# MSP432P401Y register map
Vendor: Texas Instruments; File version: 3.230
Registers are 32-bit, read-write, reset 0x0 unless marked. A register's access mark holds for its fields unless they carry their own. Offsets are from the block's base; [hi:lo] are bit positions; {n}, {i} and the like mark numbered series.

## DMA
Base 0x4000E000
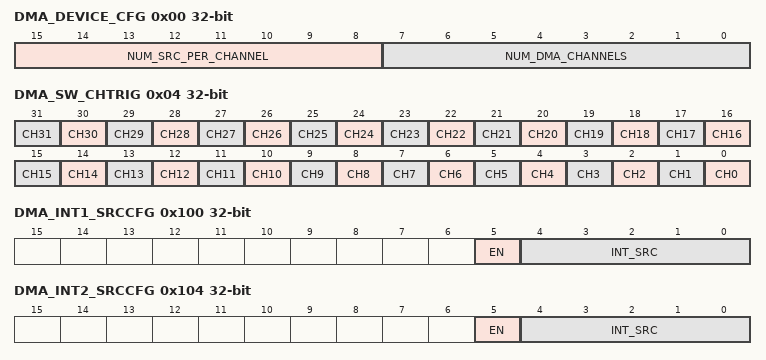
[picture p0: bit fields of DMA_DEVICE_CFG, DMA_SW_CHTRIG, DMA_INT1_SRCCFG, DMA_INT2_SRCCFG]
0x00 DMA_DEVICE_CFG ro (reset mask 0xFFFF0000) — Device Configuration Status
  [15:8] NUM_SRC_PER_CHANNEL — Number of DMA sources per channel
  [7:0] NUM_DMA_CHANNELS — Number of DMA channels available
0x04 DMA_SW_CHTRIG — Software Channel Trigger Register
  [n] CH{n} (n=0..31) — Write 1, triggers DMA_CHANNEL{n}
{0x10+4i} DMA_CH_SRCCFG[{i}] (i=0..31) — Channel n Source Configuration Register
  [7:0] DMA_SRC — Device level DMA source mapping to channel input
0x100 DMA_INT1_SRCCFG — Interrupt 1 Source Channel Configuration
  [5] EN — Enables DMA_INT1 mapping
  [4:0] INT_SRC — Controls which channel's completion event is mapped as a source of this Interrupt
0x104 DMA_INT2_SRCCFG — Interrupt 2 Source Channel Configuration Register
  [5] EN — Enables DMA_INT2 mapping
  [4:0] INT_SRC — Controls which channel's completion event is mapped as a source of this Interrupt
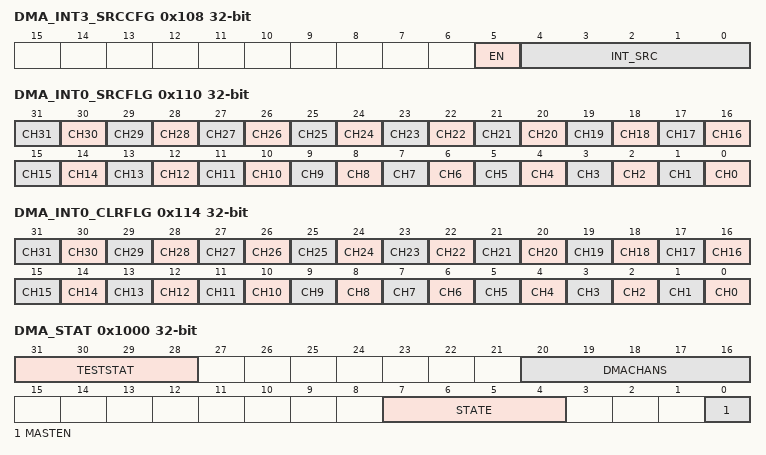
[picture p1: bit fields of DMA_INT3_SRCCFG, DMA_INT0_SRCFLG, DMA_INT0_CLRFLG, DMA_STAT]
0x108 DMA_INT3_SRCCFG — Interrupt 3 Source Channel Configuration Register
  [5] EN — Enables DMA_INT3 mapping
  [4:0] INT_SRC — Controls which channel's completion event is mapped as a source of this Interrupt
0x110 DMA_INT0_SRCFLG ro — Interrupt 0 Source Channel Flag Register
  [n] CH{n} (n=0..31) — Channel {n} was the source of DMA_INT0
0x114 DMA_INT0_CLRFLG wo reset not defined — Interrupt 0 Source Channel Clear Flag Register
  [n] CH{n} (n=0..31) — Clear corresponding DMA_INT0_SRCFLG_REG
0x1000 DMA_STAT ro (reset mask 0xF00FFFF) — Status Register
  [31:28] TESTSTAT — To reduce the gate count the controller can be configured to exclude the integration test logic. The values 2h to Fh are Reserved.
    on read: 0=Controller does not include the integration test logic; 1=Controller includes the integration test logic
  [20:16] DMACHANS — Number of available DMA channels minus one.
    on read: 0=Controller configured to use 1 DMA channel; 1=Controller configured to use 2 DMA channels; 30=Controller configured to use 31 DMA channels; 31=Controller configured to use 32 DMA channels
  [7:4] STATE — Current state of the control state machine. State can be one of the following:
    on read: 0=idle; 1=reading channel controller data; 2=reading source data end pointer; 3=reading destination data end pointer; 4=reading source data; 5=writing destination data; 6=waiting for DMA request to clear; 7=writing channel controller data; 8=stalled; 9=done; 10=peripheral scatter-gather transition
  [0] MASTEN — Enable status of the controller
    on read: 0=Controller disabled; 1=Controller enabled
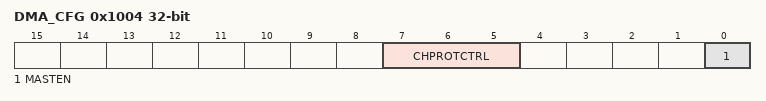
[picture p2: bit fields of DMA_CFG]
0x1004 DMA_CFG wo reset not defined — Configuration Register
  [7:5] CHPROTCTRL — Sets the AHB-Lite protection by controlling the HPROT[3:1] signal levels as follows: Bit [7] Controls HPROT[3] to indicate if a cacheable access is occurring. Bit [6] Controls HPROT[2] to indicate if a bufferable access is occurring. Bit [5] Controls HPROT[1] to indicate if a privileged access is occurring. Note: When bit [n] = 1 then the corresponding HPROT is HIGH. When bit [n] = 0 then the corresponding HPROT is LOW.
  [0] MASTEN — Enable status of the controller
    on write: 0=Controller disabled; 1=Controller enabled
0x1008 DMA_CTLBASE — Channel Control Data Base Pointer Register
  [31:5] ADDR — Pointer to the base address of the primary data structure.
0x100C DMA_ALTBASE ro (reset mask 0xFFFFFF00) — Channel Alternate Control Data Base Pointer Register
  [31:0] ADDR — Base address of the alternate data structure
0x1010 DMA_WAITSTAT ro — Channel Wait on Request Status Register
  [31:0] WAITREQ — Channel wait on request status.
    on read: 0=dma_waitonreq[C] is LOW; 1=dma_waitonreq[C] is HIGH
0x1014 DMA_SWREQ wo reset not defined — Channel Software Request Register
  [31:0] CHNL_SW_REQ — Set the appropriate bit to generate a software DMA request on the corresponding DMA channel. Writing to a bit where a DMA channel is not implemented does not create a DMA request for that channel.
    on write: 0=Does not create a DMA request for the channel; 1=Creates a DMA request for the channel
0x1018 DMA_USEBURSTSET — Channel Useburst Set Register
  [31:0] SET — Returns the useburst status, or disables dma_sreq from generating DMA requests.
    on read: 0=SET_0_READ (DMA channel C responds to requests that it receives on dma_req[C] or dma_sreq[C]. The controller performs 2R, or single, bus transfers.); 1=SET_1_READ (DMA channel C does not respond to requests that it receives on dma_sreq[C]. The controller only responds to dma_req[C] requests and performs 2R transfers.) | on write: 0=SET_0_WRITE (No effect. Use the DMA_USEBURST_CLR Register to set bit [C] to 0.); 1=SET_1_WRITE (Disables dma_sreq[C] from generating DMA requests. The controller performs 2R transfers. Writing to a bit where a DMA channel is not implemented has no effect.)
0x101C DMA_USEBURSTCLR wo reset not defined — Channel Useburst Clear Register
  [31:0] CLR — Set the appropriate bit to enable dma_sreq to generate requests.
    on write: 0=No effect. Use the DMA_USEBURST_SET Register to disable dma_sreq from generating requests.; 1=Enables dma_sreq[C] to generate DMA requests. Writing to a bit where a DMA channel is not implemented has no effect.
0x1020 DMA_REQMASKSET — Channel Request Mask Set Register
  [31:0] SET — Returns the request mask status of dma_req and dma_sreq, or disables the corresponding channel from generating DMA requests.
    on read: 0=SET_0_READ (External requests are enabled for channel C.); 1=SET_1_READ (External requests are disabled for channel C.) | on write: 0=SET_0_WRITE (No effect. Use the DMA_REQMASKCLR Register to enable DMA requests.); 1=SET_1_WRITE (Disables dma_req[C] and dma_sreq[C] from generating DMA requests. Writing to a bit where a DMA channel is not implemented has no effect.)
0x1024 DMA_REQMASKCLR wo reset not defined — Channel Request Mask Clear Register
  [31:0] CLR — Set the appropriate bit to enable DMA requests for the channel corresponding to dma_req and dma_sreq.
    on write: 0=No effect. Use the DMA_REQMASKSET Register to disable dma_req and dma_sreq from generating requests.; 1=Enables dma_req[C] or dma_sreq[C] to generate DMA requests. Writing to a bit where a DMA channel is not implemented has no effect.
0x1028 DMA_ENASET — Channel Enable Set Register
  [31:0] SET — Returns the enable status of the channels, or enables the corresponding channels.
    on read: 0=SET_0_READ (Channel C is disabled.); 1=SET_1_READ (Channel C is enabled.) | on write: 0=SET_0_WRITE (No effect. Use the DMA_ENACLR Register to disable a channel.); 1=SET_1_WRITE (Enables channel C. Writing to a bit where a DMA channel is not implemented has no effect.)
0x102C DMA_ENACLR wo reset not defined — Channel Enable Clear Register
  [31:0] CLR — Set the appropriate bit to disable the corresponding DMA channel. Note: The controller disables a channel, by setting the appropriate bit, when: a) it completes the DMA cycle b) it reads a channel_cfg memory location which has cycle_ctrl = b000 c) an ERROR occurs on the AHB-Lite bus.
    on write: 0=No effect. Use the DMA_ENASET Register to enable DMA channels.; 1=Disables channel C. Writing to a bit where a DMA channel is not implemented has no effect.
0x1030 DMA_ALTSET — Channel Primary-Alternate Set Register
  [31:0] SET
    on read: 0=SET_0_READ (DMA channel C is using the primary data structure.); 1=SET_1_READ (DMA channel C is using the alternate data structure.) | on write: 0=SEL_0_WRITE (No effect. Use the DMA_ALTCLR Register to set bit [C] to 0.); 1=SEL_1_WRITE (Selects the alternate data structure for channel C. Writing to a bit where a DMA channel is not implemented has no effect.)
0x1034 DMA_ALTCLR wo reset not defined — Channel Primary-Alternate Clear Register
  [31:0] CLR
    on write: 0=No effect. Use the DMA_ALTSET Register to select the alternate data structure.; 1=Selects the primary data structure for channel C. Writing to a bit where a DMA channel is not implemented has no effect.
0x1038 DMA_PRIOSET — Channel Priority Set Register
  [31:0] SET — Returns the channel priority mask status, or sets the channel priority to high.
    on read: 0=SET_0_READ (DMA channel C is using the default priority level.); 1=SET_1_READ (DMA channel C is using a high priority level.) | on write: 0=SET_0_WRITE (No effect. Use the DMA_PRIOCLR Register to set channel C to the default priority level.); 1=SET_1_WRITE (Channel C uses the high priority level. Writing to a bit where a DMA channel is not implemented has no effect.)
0x103C DMA_PRIOCLR wo reset not defined — Channel Priority Clear Register
  [31:0] CLR — Set the appropriate bit to select the default priority level for the specified DMA channel.
    on write: 0=No effect. Use the DMA_PRIOSET Register to set channel C to the high priority level.; 1=Channel C uses the default priority level. Writing to a bit where a DMA channel is not implemented has no effect.
0x104C DMA_ERRCLR — Bus Error Clear Register
  [0] ERRCLR — Returns the status of dma_err, or sets the signal LOW. For test purposes, use the ERRSET register to set dma_err HIGH. Note: If you deassert dma_err at the same time as an ERROR occurs on the AHB-Lite bus, then the ERROR condition takes precedence and dma_err remains asserted.
    on read: 0=ERRCLR_0_READ (dma_err is LOW); 1=ERRCLR_1_READ (dma_err is HIGH.) | on write: 0=ERRCLR_0_WRITE (No effect, status of dma_err is unchanged.); 1=ERRCLR_1_WRITE (Sets dma_err LOW.)
